# PIC32MM0064GPM036 device description
Architecture: MIPS; Family: PIC32MM1387; Series: PIC32MM
Registers are 32-bit, read-write, no defined reset value unless marked. A register's access mark holds for its fields unless they carry their own. Offsets are from the block's base; [hi:lo] are bit positions; 'fields as' and 'values as' point back to an identical list.

## NVM
Instances: NVM 0x1f802930 in periph0
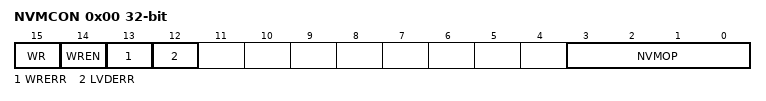
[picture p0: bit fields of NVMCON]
0x00 NVMCON
  [15] WR, [14] WREN, [13] WRERR, [12] LVDERR, [3:0] NVMOP

## RCON
Instances: RCON 0x1f802680 in periph0
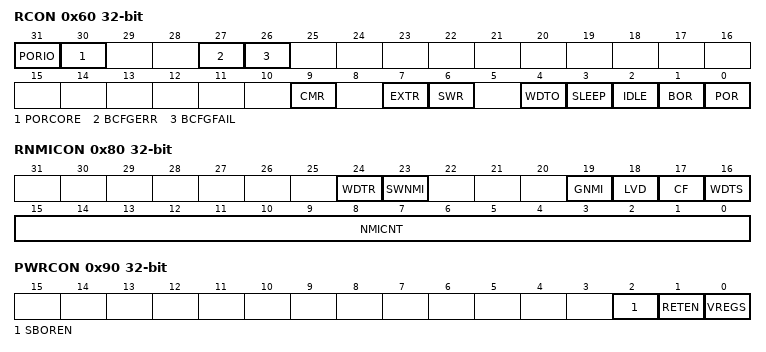
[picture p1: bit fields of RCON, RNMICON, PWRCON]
0x60 RCON — Reset Control Register
  [31] PORIO
  [30] PORCORE
  [27] BCFGERR
  [26] BCFGFAIL
  [9] CMR — Configuration Mismatch Reset Flag bit
    1=A Configuration Mismatch Reset has occurred; 0=A Configuration Mismatch Reset has not occurred
  [7] EXTR — External Reset Pin Flag bit
    1=Master Clear (pin) Reset has occurred; 0=Master Clear (pin) Reset has not occurred
  [6] SWR — Software Reset Flag bit
    1=Software Reset was executed; 0=Software Reset was not executed
  [4] WDTO — Watchdog Timer Time-out Flag bit
    1=WDT Time-out has occurred; 0=WDT Time-out has not occurred
  [3] SLEEP — Wake From Sleep Flag bit
    1=Device was in Sleep mode; 0=Device was not in Sleep mode
  [2] IDLE — Wake From Idle Flag bit
    1=Device was in Idle mode; 0=Device was not in Idle mode
  [1] BOR — Brown-out Reset Flag bit
    1=Brown-out Reset has occurred; 0=Brown-out Reset has not occurred
  [0] POR — Power-on Reset Flag bit
    1=Power-on Reset has occurred; 0=Power-on Reset has not occurred
0x70 RSWRST wo
  [0] SWRST
0x80 RNMICON — Non-Maskable Interrupt (NMI) Control Register
  [24] WDTR — Run Time Watchdog Timer Time-Out Flag bit
    1=WDT time-out has occurred and caused a NMI; 0=WDT time-out has not occurred
  [23] SWNMI — Software NMI Trigger
    1=An NMI will be generated; 0=An NMI will not be generated
  [19] GNMI — General NMI bit
    1=A general NMI event has been detected or a user-initiated NMI event has occurred; 0=A general NMI event has not been detected
  [18] LVD
  [17] CF — Clock Fail Detect bit
    1=FSCM has detected clock failure and caused an NMI; 0=FSCM has not detected clock failure
  [16] WDTS — Watchdog Timer Time-out in Sleep Mode Flag bit
    1=WDT time-out has occurred during Sleep mode and caused a wake-up from sleep; 0=WDT time-out has not occurred during Sleep mode
  [15:0] NMICNT — NMI Reset Counter Value bits
    0xffff=65535 SYSCLK cycles before a device Reset occurs; 2=2 SYSCLK cycle before a device Reset occurs; 1=1 SYSCLK cycle before a device Reset occurs; 0=No delay between NMI assertion and device Reset event
0x90 PWRCON
  [2] SBOREN
  [1] RETEN
  [0] VREGS — Voltage Regulator Stand-by Enable bit
    1=Voltage regulator will remain active during Sleep; 0=Voltage regulator will go to Stand-by mode during Sleep

## RTCC
Instances: RTCC 0x1f800000 in periph0
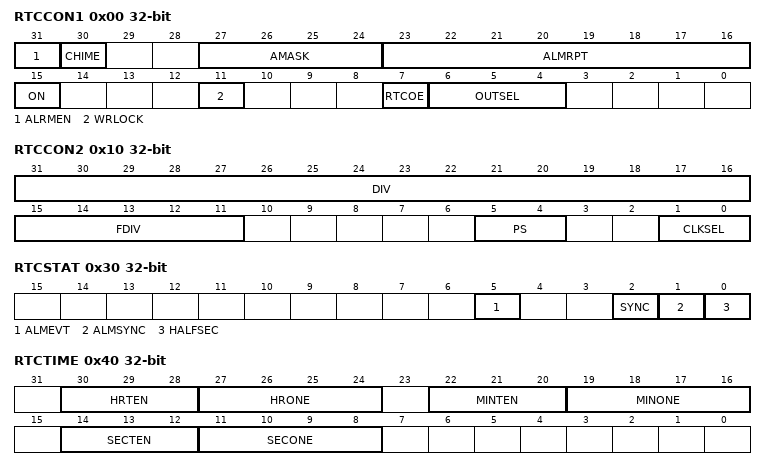
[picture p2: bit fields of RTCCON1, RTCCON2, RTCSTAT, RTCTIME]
0x00 RTCCON1
  [31] ALRMEN
  [30] CHIME
  [27:24] AMASK — Alarm Mask Configuration bits
    0=Every half-second; 1=Every second; 2=Every 10 seconds; 3=Every minute; 4=Every 10 minutes; 5=Every hour; 6=Once a day; 7=Once a week; 8=Once a month; 9=Once a year (or once every four years when configured for February 29th)
  [23:16] ALMRPT — Alarm Repeat Counter Value bits
  [15] ON — RTCC On bit
    1=RTCC module is enabled; 0=RTCC module is disabled
  [11] WRLOCK
  [7] RTCOE — RTCC Output Enable bit
    1=RTCC clock output is enabled; signal selected by OUTSEL[2:0] is presented on the RTCC pin; 0=RTCC clock output is disabled
  [6:4] OUTSEL — RTCC Signal Output Select bits
    2=RTCC input clock source (based on the combination of the RTCCON2 bits, DIV[15:0] and PS[1:0]); 1=Seconds Clock is presented on the RTCC pin; 0=Alarm Pulse is presented on the RTCC pin when the alarm interrupt is triggered
0x10 RTCCON2
  [31:16] DIV
  [15:11] FDIV
  [5:4] PS — RTCC Prescaler
    3=1:256; 2=1:64; 1=1:16; 0=1:1
  [1:0] CLKSEL — RTCC Clock Select bits
    3=PBCLK (RTCC uses peripheral clock); 2=PWRLCLK (RTCC uses the clock on PWRLCLK pin); 1=LPRC (RTCC uses the internal 32 kHz oscillator (LPRC)); 0=SOSC (RTCC uses the external 32.768 kHz Secondary Oscillator (SOSC))
0x30 RTCSTAT ro
  [5] ALMEVT, [2] SYNC, [1] ALMSYNC, [0] HALFSEC
0x40 RTCTIME
  [30:28] HRTEN, [27:24] HRONE, [22:20] MINTEN, [19:16] MINONE, [14:12] SECTEN, [11:8] SECONE
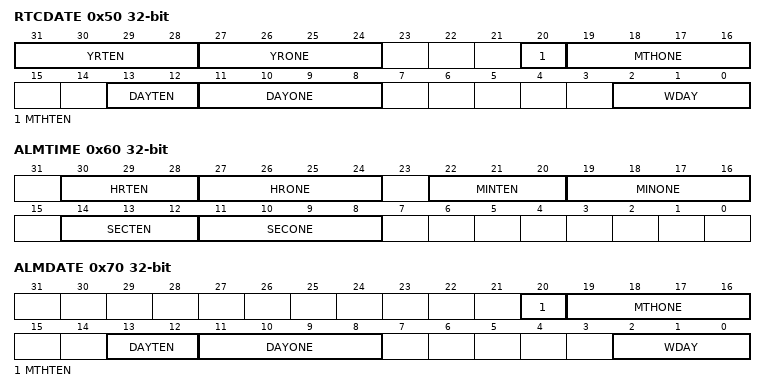
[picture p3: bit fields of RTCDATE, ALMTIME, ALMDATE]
0x50 RTCDATE
  [31:28] YRTEN, [27:24] YRONE, [20] MTHTEN, [19:16] MTHONE, [13:12] DAYTEN, [11:8] DAYONE, [2:0] WDAY
0x60 ALMTIME
  fields as RTCTIME
0x70 ALMDATE
  [20] MTHTEN, [19:16] MTHONE, [13:12] DAYTEN, [11:8] DAYONE, [2:0] WDAY

## TMR1
Instances: TMR1 0x1f808000 in periph1
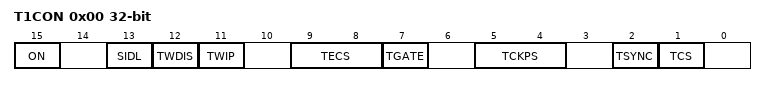
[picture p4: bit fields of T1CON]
0x00 T1CON — TYPE A TIMER CONTROL REGISTER
  [15] ON — Timer On bit
    1=Timer is enabled; 0=Timer is disabled
  [13] SIDL — Stop in Idle Mode bit
    1=Discontinue operation when device enters Idle mode; 0=Continue operation even in Idle mode
  [12] TWDIS — Asynchronous Timer Write Disable bit
    1=Writes to TMR1 are ignored until pending write operation completes; 0=Back-to-back writes are enabled (Legacy Asynchronous Timer functionality)
  [11] TWIP — Asynchronous Timer Write in Progress bit
    1=(In Asynchronous Timer mode) Asynchronous write to TMR1 register in progress / (In Synchronous Timer mode)bit is read as 0; 0=In Asynchronous Timer mode Asynchronous write to TMR1 register complete / (In Synchronous Timer mode)bit is read as 0
  [9:8] TECS — Timer1 External Clock Selection bits
    2=LPRC (External clock comes from the LPRC); 1=T1CK_PIN (External clock comes from the T1CK pin); 0=SOSC (External clock comes from the SOSC)
  [7] TGATE — Timer Gated Time Accumulation Enable bit
    1=(When TCS is 0) Gated time accumulation is enabled / (When TCS is 1) bit is ignored; 0=(When TCS is 0) Gated time accumulation is disabled / (When TCS is 1) bit is ignored
  [5:4] TCKPS — Timer Input Clock Prescale Select bits
    3=1:256 prescale value; 2=1:64 prescale value; 1=1:8 prescale value; 0=1:1 prescale value
  [2] TSYNC — Timer External Clock Input Synchronization Selection bit
    1=(When TCS is 1) External clock input is synchronized / (When TCS is 0) This bit is ignored; 0=(When TCS is 1) External clock input is not synchronized / (When TCS is 0) This bit is ignored
  [1] TCS — Timer Clock Source Select bit
    1=External clock is defined by the TECS bits; 0=Internal peripheral clock
0x10 TMR1
0x20 PR1

## TMR
Instances: TMR 0x1f808040 in periph1
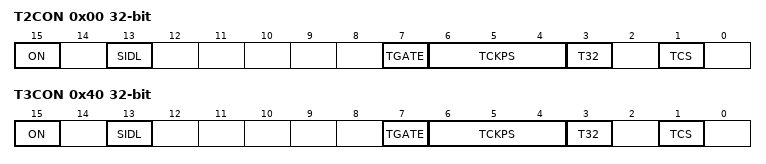
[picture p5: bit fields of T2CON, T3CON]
0x00 T2CON — Type B Timer Control Register
  [15] ON — Timer On bit
    1=Module is enabled; 0=Module is disabled
  [13] SIDL — Stop in Idle Mode bit
    1=Discontinue operation when device enters Idle mode; 0=Continue operation even in Idle mode
  [7] TGATE — Timer Gated Time Accumulation Enable bit
    1=(When TCS is 1): This bit is ignored and is read as 0 / (When TCS=0): Gated time accumulation is enabled; 0=(When TCS is 1): This bit is ignored and is read as 0 / (When TCS=0): Gated time accumulation is disabled
  [6:4] TCKPS — Timer Input Clock Prescale Select bits
    7=1:256 prescale value; 6=1:64 prescale value; 5=1:32 prescale value; 4=1:16 prescale value; 3=1:8 prescale value; 2=1:4 prescale value; 1=1:2 prescale value; 0=1:1 prescale value
  [3] T32 — 32-Bit Timer Mode Select bit
    1=Odd numbered and even numbered timers form a 32-bit timer; 0=Odd numbered and even numbered timers form separate 16-bit timers
  [1] TCS — Timer Clock Source Select bit
    1=External clock from TxCK pin; 0=Internal peripheral clock
0x10 TMR2
0x20 PR2
0x40 T3CON — Type B Timer Control Register
  fields as T2CON
0x50 TMR3
0x60 PR3

## UDID
Instances: UDID 0x1fc41840 in UDIDx
0x00 UDID1 ro
0x04 UDID2 ro
0x08 UDID3 ro
0x0C UDID4 ro
0x10 UDID5 ro

## WDT
Instances: WDT 0x1f803990 in periph0
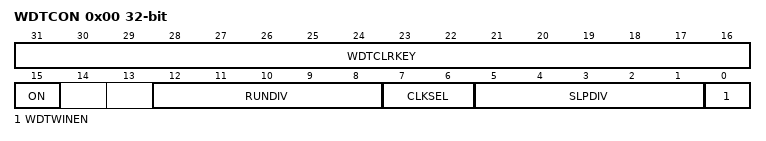
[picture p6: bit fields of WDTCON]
0x00 WDTCON — Watchdog Timer Control Register
  [31:16] WDTCLRKEY — Watchdog Timer Clear Key bits
  [15] ON — Watchdog Timer Enable bit
    1=The WDT module is enabled; 0=The WDT module is disabled
  [12:8] RUNDIV — Watchdog Timer Postscaler Value in Run Mode bits
  [7:6] CLKSEL
  [5:1] SLPDIV
  [0] WDTWINEN — Watchdog Timer Window Enable bit
    1=Enable windowed Watchdog Timer; 0=Disable windowed Watchdog Timer
